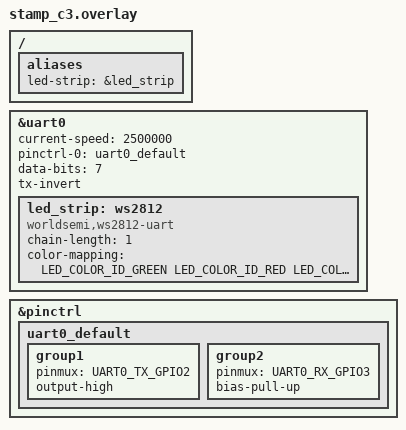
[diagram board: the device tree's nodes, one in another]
#include <zephyr/dt-bindings/gpio/gpio.h>
#include <zephyr/dt-bindings/led/led.h>


#include <zephyr/dt-bindings/led/led.h>

&uart0 {
	status = "okay";
	current-speed = <2500000>;
	pinctrl-0 = <&uart0_default>;
	pinctrl-names = "default";
	data-bits = <7>;
    tx-invert;
        led_strip: ws2812 {
                compatible = "worldsemi,ws2812-uart";

                /* WS2812 */
                chain-length = <1>; /* arbitrary; change at will */
                color-mapping = <LED_COLOR_ID_GREEN
                                 LED_COLOR_ID_RED
                                 LED_COLOR_ID_BLUE>;
        };
};


&pinctrl {
	uart0_default: uart0_default {
		group1 {
			pinmux = <UART0_TX_GPIO2>;
			output-high;
		};
		group2 {
			pinmux = <UART0_RX_GPIO3>;
			bias-pull-up;
		};
	};
};

/ {
        aliases {
                led-strip = &led_strip;
        };
};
